# STM32H7P5 register map
File version: 0.1
CPU: CM7 r1p2, little endian, MPU, FPU, 4 interrupt priority bits
Registers are 32-bit, read-write, reset 0x0 unless marked. A register's access mark holds for its fields unless they carry their own. Offsets are from the block's base; [hi:lo] are bit positions; 'fields as' and 'values as' point back to an identical list.

## DAC — DAC address block description
Base 0x48027000
Same registers: DAC34 0x48027400, DAC56 0x48027800, DAC78 0x48027C00
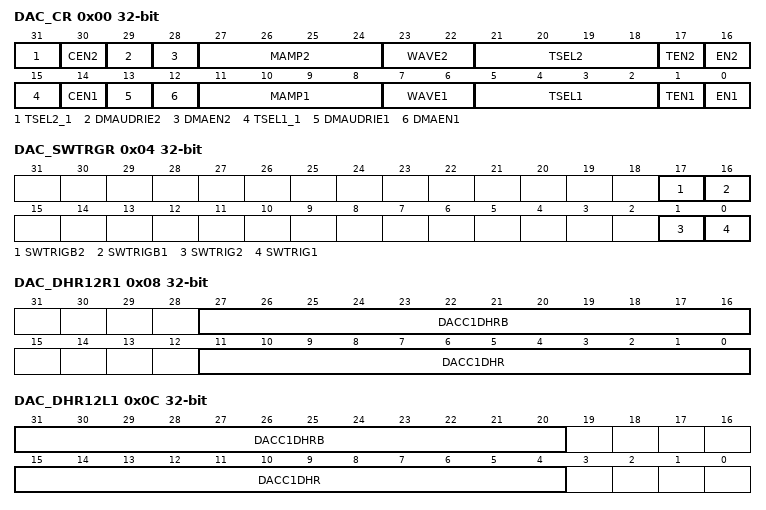
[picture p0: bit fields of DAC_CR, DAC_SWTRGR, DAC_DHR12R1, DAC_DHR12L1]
0x00 DAC_CR — DAC control register
  [31] TSEL2_1 — TSEL2 [4]
  [30] CEN2 — DAC channel2 calibration enable
    0=DAC channel2 in normal operating mode; 1=DAC channel2 in calibration mode
  [29] DMAUDRIE2 — DAC channel2 DMA underrun interrupt enable
    0=DAC channel2 DMA underrun interrupt disabled; 1=DAC channel2 DMA underrun interrupt enabled
  [28] DMAEN2 — DAC channel2 DMA enable
    0=DAC channel2 DMA mode disabled; 1=DAC channel2 DMA mode enabled
  [27:24] MAMP2 — DAC channel2 mask/amplitude selector
    0=Unmask bit0 of LFSR/ triangle amplitude equal to 1; 1=Unmask bits[1:0] of LFSR/ triangle amplitude equal to 3; 2=Unmask bits[2:0] of LFSR/ triangle amplitude equal to 7; 3=Unmask bits[3:0] of LFSR/ triangle amplitude equal to 15; 4=Unmask bits[4:0] of LFSR/ triangle amplitude equal to 31; 5=Unmask bits[5:0] of LFSR/ triangle amplitude equal to 63; 6=Unmask bits[6:0] of LFSR/ triangle amplitude equal to 127; 7=Unmask bits[7:0] of LFSR/ triangle amplitude equal to 255; 8=Unmask bits[8:0] of LFSR/ triangle amplitude equal to 511; 9=Unmask bits[9:0] of LFSR/ triangle amplitude equal to 1023; 10=Unmask bits[10:0] of LFSR/ triangle amplitude equal to 2047
  [23:22] WAVE2 — DAC channel2 noise/triangle wave generation enable
    0=wave generation disabled; 1=Noise wave generation enabled; 2=Triangle wave generation enabled; 3=Sawtooth wave generation enabled
  [21:18] TSEL2 — TSEL2[3:0]: DAC channel2 trigger selection
    0=SWTRIG2; 1=dac_ch2_trg1; 2=dac_ch2_trg2
  [17] TEN2 — DAC channel2 trigger enable
    0=DAC channel2 trigger disabled and data written into the DAC_DHR2 register are transferred one dac_ker_ck clock cycle later to the DAC_DOR2 register; 1=DAC channel2 trigger enabled and data from the DAC_DHR2 register are transferred three dac_ker_ck clock cycles later to the DAC_DOR2 register
  [16] EN2 — DAC channel2 enable
    0=DAC channel2 disabled; 1=DAC channel2 enabled
  [15] TSEL1_1 — TSEL1[4]
  [14] CEN1 — DAC channel1 calibration enable
    0=DAC channel1 in normal operating mode; 1=DAC channel1 in calibration mode
  [13] DMAUDRIE1 — DAC channel1 DMA Underrun Interrupt enable
    0=DAC channel1 DMA Underrun Interrupt disabled; 1=DAC channel1 DMA Underrun Interrupt enabled
  [12] DMAEN1 — DAC channel1 DMA enable
    0=DAC channel1 DMA mode disabled; 1=DAC channel1 DMA mode enabled
  [11:8] MAMP1 — DAC channel1 mask/amplitude selector
    values as MAMP2
  [7:6] WAVE1 — DAC channel1 noise/triangle wave generation enable
    values as WAVE2
  [5:2] TSEL1 — TSEL1[3:0]: DAC channel1 trigger selection
    0=SWTRIG1; 1=dac_ch1_trg1; 2=dac_ch1_trg2
  [1] TEN1 — DAC channel1 trigger enable
    0=DAC channel1 trigger disabled and data written into the DAC_DHR1 register are transferred one dac_ker_ck clock cycle later to the DAC_DOR1 register; 1=DAC channel1 trigger enabled and data from the DAC_DHR1 register are transferred three dac_ker_ck clock cycles later to the DAC_DOR1 register
  [0] EN1 — DAC channel1 enable
    0=DAC channel1 disabled; 1=DAC channel1 enabled
0x04 DAC_SWTRGR wo — DAC software trigger register
  [17] SWTRIGB2 — DAC channel2 software trigger B
    0=No trigger; 1=Trigger for sawtooth increment
  [16] SWTRIGB1 — DAC channel1 software trigger B
    0=No trigger; 1=Trigger for sawtooth increment
  [1] SWTRIG2 — DAC channel2 software trigger
    0=No trigger; 1=Trigger
  [0] SWTRIG1 — DAC channel1 software trigger
    0=No trigger; 1=Trigger
0x08 DAC_DHR12R1 — DAC channel1 12-bit right-aligned data holding register
  [27:16] DACC1DHRB — DAC channel1 12-bit right-aligned data B
  [11:0] DACC1DHR — DAC channel1 12-bit right-aligned data
0x0C DAC_DHR12L1 — DAC channel1 12-bit left aligned data holding register
  [31:20] DACC1DHRB — DAC channel1 12-bit left-aligned data B
  [15:4] DACC1DHR — DAC channel1 12-bit left-aligned data
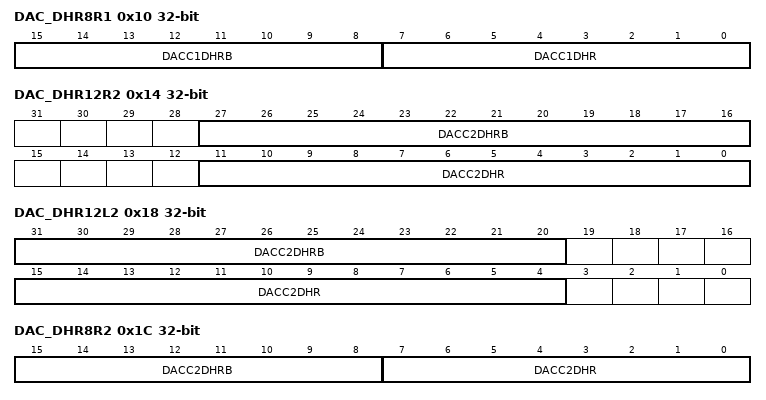
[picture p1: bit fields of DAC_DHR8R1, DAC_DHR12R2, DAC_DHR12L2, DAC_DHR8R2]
0x10 DAC_DHR8R1 — DAC channel1 8-bit right aligned data holding register
  [15:8] DACC1DHRB — DAC channel1 8-bit right-aligned data
  [7:0] DACC1DHR — DAC channel1 8-bit right-aligned data
0x14 DAC_DHR12R2 — DAC channel2 12-bit right aligned data holding register
  [27:16] DACC2DHRB — DAC channel2 12-bit right-aligned data
  [11:0] DACC2DHR — DAC channel2 12-bit right-aligned data
0x18 DAC_DHR12L2 — DAC channel2 12-bit left aligned data holding register
  [31:20] DACC2DHRB — DAC channel2 12-bit left-aligned data B
  [15:4] DACC2DHR — DAC channel2 12-bit left-aligned data
0x1C DAC_DHR8R2 — DAC channel2 8-bit right-aligned data holding register
  [15:8] DACC2DHRB — DAC channel2 8-bit right-aligned data
  [7:0] DACC2DHR — DAC channel2 8-bit right-aligned data
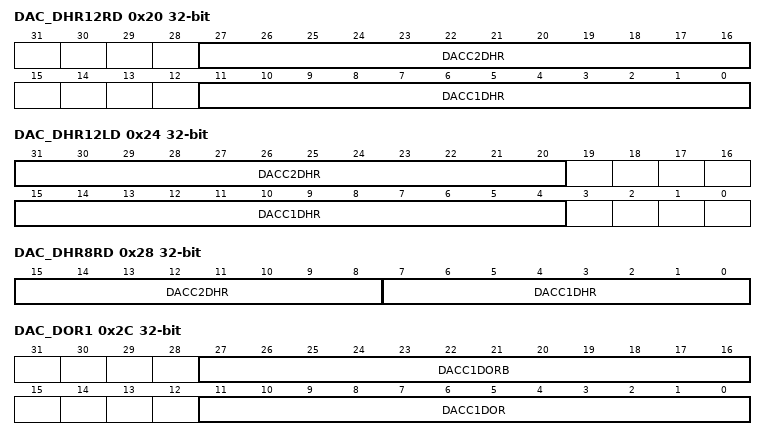
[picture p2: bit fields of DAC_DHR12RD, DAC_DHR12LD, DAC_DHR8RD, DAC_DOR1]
0x20 DAC_DHR12RD — Dual DAC 12-bit right-aligned data holding register
  [27:16] DACC2DHR — DAC channel2 12-bit right-aligned data
  [11:0] DACC1DHR — DAC channel1 12-bit right-aligned data
0x24 DAC_DHR12LD — Dual DAC 12-bit left aligned data holding register
  [31:20] DACC2DHR — DAC channel2 12-bit left-aligned data
  [15:4] DACC1DHR — DAC channel1 12-bit left-aligned data
0x28 DAC_DHR8RD — Dual DAC 8-bit right aligned data holding register
  [15:8] DACC2DHR — DAC channel2 8-bit right-aligned data
  [7:0] DACC1DHR — DAC channel1 8-bit right-aligned data
0x2C DAC_DOR1 ro — DAC channel1 data output register
  [27:16] DACC1DORB — DAC channel1 data output
  [11:0] DACC1DOR — DAC channel1 data output
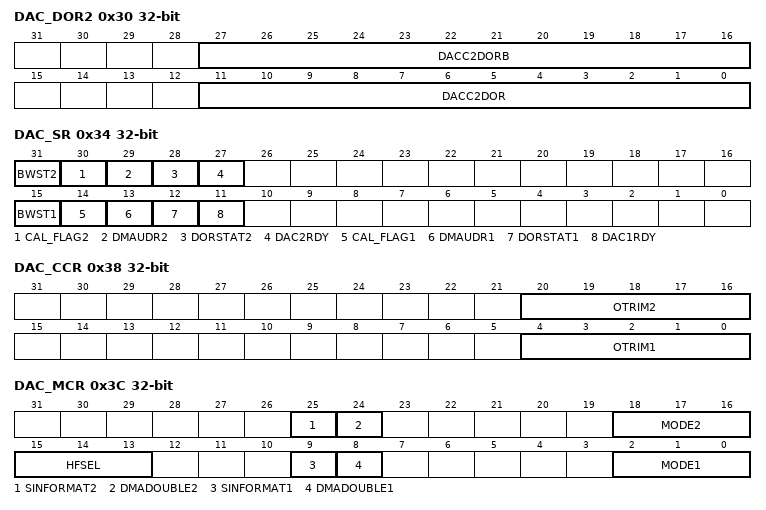
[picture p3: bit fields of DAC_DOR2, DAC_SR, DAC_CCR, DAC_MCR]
0x30 DAC_DOR2 ro — DAC channel2 data output register
  [27:16] DACC2DORB — DAC channel2 data output
  [11:0] DACC2DOR — DAC channel2 data output
0x34 DAC_SR — DAC status register
  [31] BWST2 ro — DAC channel2 busy writing sample time flag
    0=There is no write operation of DAC_SHSR2 ongoing: DAC_SHSR2 can be written; 1=There is a write operation of DAC_SHSR2 ongoing: DAC_SHSR2 cannot be written
  [30] CAL_FLAG2 ro — DAC channel2 calibration offset status
    0=calibration trimming value is lower than the offset correction value; 1=calibration trimming value is equal or greater than the offset correction value
  [29] DMAUDR2 — DAC channel2 DMA underrun flag
    0=No DMA underrun error condition occurred for DAC channel2; 1=DMA underrun error condition occurred for DAC channel2 (the currently selected trigger is driving DAC channel2 conversion at a frequency higher than the DMA service capability rate)
  [28] DORSTAT2 ro — DAC channel2 output register status bit
    0=DOR[11:0] is used actual DAC output; 1=DORB[11:0] is used actual DAC output
  [27] DAC2RDY ro — DAC channel2 ready status bit
    0=DAC channel2 is not yet ready to accept the trigger nor output data; 1=DAC channel2 is ready to accept the trigger or output data
  [15] BWST1 ro — DAC channel1 busy writing sample time flag
    0=There is no write operation of DAC_SHSR1 ongoing: DAC_SHSR1 can be written; 1=There is a write operation of DAC_SHSR1 ongoing: DAC_SHSR1 cannot be written
  [14] CAL_FLAG1 ro — DAC channel1 calibration offset status
    values as CAL_FLAG2
  [13] DMAUDR1 — DAC channel1 DMA underrun flag
    0=No DMA underrun error condition occurred for DAC channel1; 1=DMA underrun error condition occurred for DAC channel1 (the currently selected trigger is driving DAC channel1 conversion at a frequency higher than the DMA service capability rate)
  [12] DORSTAT1 ro — DAC channel1 output register status bit
    values as DORSTAT2
  [11] DAC1RDY ro — DAC channel1 ready status bit
    0=DAC channel1 is not yet ready to accept the trigger nor output data; 1=DAC channel1 is ready to accept the trigger or output data
0x38 DAC_CCR (reset mask 0xFF00FF00) — DAC calibration control register
  [20:16] OTRIM2 — DAC channel2 offset trimming value
  [4:0] OTRIM1 — DAC channel1 offset trimming value
0x3C DAC_MCR — DAC mode control register
  [25] SINFORMAT2 — Enable signed format for DAC channel2
    0=Input data is in unsigned format; 1=Input data is in signed format (2's complement)
  [24] DMADOUBLE2 — DAC channel2 DMA double data mode
    0=DMA normal mode selected; 1=DMA double data mode selected
  [18:16] MODE2 — DAC channel2 mode
    0=DAC channel2 is connected to external pin with Buffer enabled; 1=DAC channel2 is connected to external pin and to on chip peripherals with buffer enabled; 2=DAC channel2 is connected to external pin with buffer disabled; 3=DAC channel2 is connected to on chip peripherals with Buffer disabled; 4=DAC channel2 is connected to external pin with Buffer enabled; 5=DAC channel2 is connected to external pin and to on chip peripherals with Buffer enabled; 6=DAC channel2 is connected to external pin with Buffer disabled; 7=DAC channel2 is connected to on chip peripherals with Buffer disabled
  [15:13] HFSEL — High frequency interface mode selection
    0=High frequency interface mode disabled; 1=High frequency interface mode enabled for 80MHzless than or equal todac_ker_ckless than or equal toxA0MHz; 2=High frequency interface mode enabled for xA0MHzless than or equal todac_ker_ck
  [9] SINFORMAT1 — Enable signed format for DAC channel1
    values as SINFORMAT2
  [8] DMADOUBLE1 — DAC channel1 DMA double data mode
    0=DMA normal mode selected; 1=DMA double data mode selected
  [2:0] MODE1 — DAC channel1 mode
    0=DAC channel1 is connected to external pin with Buffer enabled; 1=DAC channel1 is connected to external pin and to on chip peripherals with Buffer enabled; 2=DAC channel1 is connected to external pin with Buffer disabled; 3=DAC channel1 is connected to on chip peripherals with Buffer disabled; 4=DAC channel1 is connected to external pin with Buffer enabled; 5=DAC channel1 is connected to external pin and to on chip peripherals with Buffer enabled; 6=DAC channel1 is connected to external pin with Buffer disabled; 7=DAC channel1 is connected to on chip peripherals with Buffer disabled
0x40 DAC_SHSR1 — DAC channel1 sample and hold sample time register
  [9:0] TSAMPLE1 — DAC channel1 sample time (only valid in sample and hold mode)
0x44 DAC_SHSR2 — DAC channel2 sample and hold sample time register
  [9:0] TSAMPLE2 — DAC channel2 sample time (only valid in sample and hold mode)
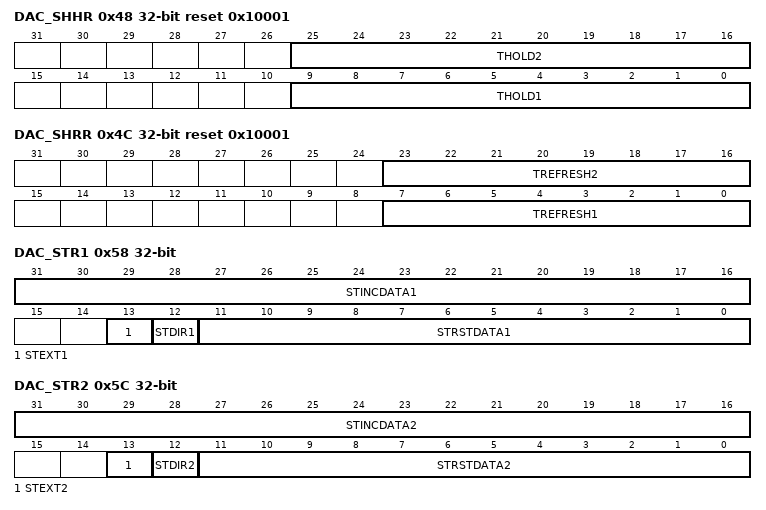
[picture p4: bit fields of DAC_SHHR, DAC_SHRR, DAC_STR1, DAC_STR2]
0x48 DAC_SHHR reset 0x10001 — DAC sample and hold time register
  [25:16] THOLD2 — DAC channel2 hold time (only valid in sample and hold mode).
  [9:0] THOLD1 — DAC channel1 hold time (only valid in sample and hold mode)
0x4C DAC_SHRR reset 0x10001 — DAC sample and hold refresh time register
  [23:16] TREFRESH2 — DAC channel2 refresh time (only valid in sample and hold mode)
  [7:0] TREFRESH1 — DAC channel1 refresh time (only valid in sample and hold mode)
0x58 DAC_STR1 — DAC channel1 sawtooth register
  [31:16] STINCDATA1 — DAC channel1 sawtooth increment value (12.
  [13] STEXT1 — DAC channel1 sawtooth extended setting
    0=Sawtooth reset value defined by STRSTDATA[11:0]; 1=Sawtooth reset value defined by STEXTRSTDATA[15:0]
  [12] STDIR1 — DAC channel1 sawtooth direction setting
    0=Decrement; 1=Increment
  [11:0] STRSTDATA1 — DAC channel1 sawtooth reset value
0x5C DAC_STR2 — DAC channel2 sawtooth register
  [31:16] STINCDATA2 — DAC channel2 Sawtooth increment value (12.
  [13] STEXT2 — DAC channel2 sawtooth extended setting
    0=Sawtooth reset value defined by STRSTDATA2[11:0]; 1=Sawtooth reset value defined by STEXTRSTDATA2[15:0]
  [12] STDIR2 — DAC channel2 sawtooth direction setting
    0=Decrement; 1=Increment
  [11:0] STRSTDATA2 — DAC channel2 sawtooth reset value
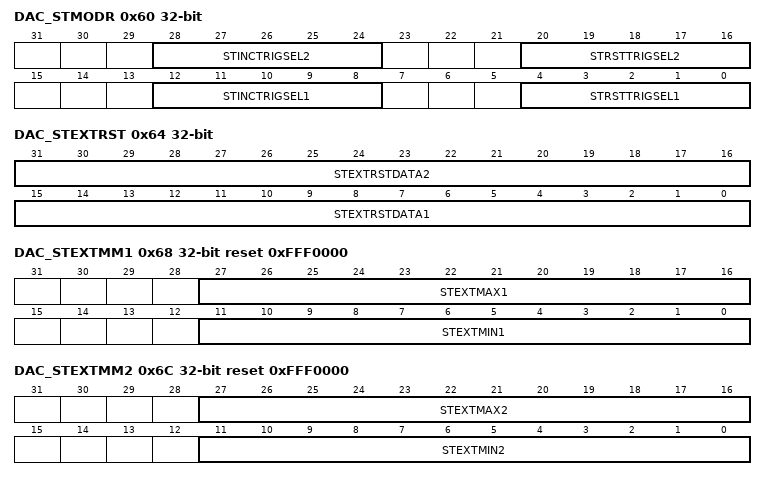
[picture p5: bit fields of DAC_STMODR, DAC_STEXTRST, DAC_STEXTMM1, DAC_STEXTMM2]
0x60 DAC_STMODR — DAC sawtooth mode register
  [28:24] STINCTRIGSEL2 — DAC channel2 sawtooth increment trigger (STINCTRIG) selection
    0=SWTRIGB2; 1=dac_inc_ch2_trg1; 31=dac_inc_ch2_trg31
  [20:16] STRSTTRIGSEL2 — DAC channel2 sawtooth reset trigger (STRSTTRIG) selection
    0=SWTRIG2; 1=dac_ch2_trg1; 31=dac_ch2_trg31
  [12:8] STINCTRIGSEL1 — DAC channel1 sawtooth increment trigger (STINCTRIG) selection
    0=SWTRIGB1; 1=dac_inc_ch1_trg1; 31=dac_inc_ch1_trg31
  [4:0] STRSTTRIGSEL1 — DAC channel1 sawtooth reset trigger (STRSTTRIG) selection
    0=SWTRIG1; 1=dac_ch1_trg1; 31=dac_ch1_trg31
0x64 DAC_STEXTRST — DAC extended sawtooth reset control register
  [31:16] STEXTRSTDATA2 — DAC channel2 extended sawtooth reset value
  [15:0] STEXTRSTDATA1 — DAC channel1 extended sawtooth reset value
0x68 DAC_STEXTMM1 reset 0xFFF0000 — DAC extended sawtooth minimum and maximum value register
  [27:16] STEXTMAX1 — DAC channel1 extended sawtooth maximum value
  [11:0] STEXTMIN1 — DAC channel1 extended sawtooth minimum value
0x6C DAC_STEXTMM2 reset 0xFFF0000 — DAC extended sawtooth minimum and maximum value register
  [27:16] STEXTMAX2 — DAC channel1 extended sawtooth maximum value
  [11:0] STEXTMIN2 — DAC channel1 extended sawtooth minimum value
0x3EC DAC_OR — DAC option register
  [3:0] OP — Option bits
    0=Output glitch control disabled; 1=Output glitch control forced to a negative level; 2=Output glich control forced to a positive level
